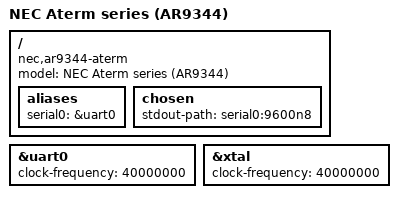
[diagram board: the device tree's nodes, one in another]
// SPDX-License-Identifier: GPL-2.0+
/*
 * Copyright (C) 2024 INAGAKI Hiroshi <musashino.open@gmail.com>
 */

/dts-v1/;
#include "ar934x.dtsi"

/ {
	model = "NEC Aterm series (AR9344)";
	compatible = "nec,ar9344-aterm", "qca,ar934x";

	aliases {
		serial0 = &uart0;
	};

	chosen {
		stdout-path = "serial0:9600n8";
	};
};

&uart0 {
	clock-frequency = <40000000>;
	status = "okay";
};

&xtal {
	clock-frequency = <40000000>;
};

/* delete unused nodes to reduce dtb size */
/delete-node/ &ehci0;
/delete-node/ &gmac0;
/delete-node/ &gmac1;
/delete-node/ &spi0;
